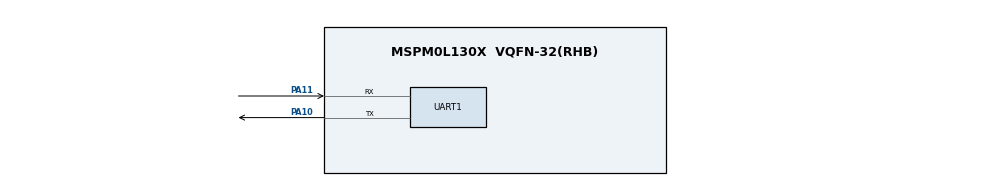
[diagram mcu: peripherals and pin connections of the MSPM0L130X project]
/**
 * @cliArgs --device "MSPM0L130X" --package "VQFN-32(RHB)" --part "Default" --product "mspm0_sdk@1.20.01.06"
 * @versions {"tool":"1.19.0+3426"}
 */

/**
 * Import the modules used in this configuration.
 */
const Board  = scripting.addModule("/ti/driverlib/Board");
const EVENT  = scripting.addModule("/ti/driverlib/EVENT");
const SYSCTL = scripting.addModule("/ti/driverlib/SYSCTL");
const UART   = scripting.addModule("/ti/driverlib/UART", {}, false);
const UART1  = UART.addInstance();

/**
 * Write custom configuration values to the imported modules.
 */
const gate6  = system.clockTree["MFCLKGATE"];
gate6.enable = true;

const gate7  = system.clockTree["MFPCLKGATE"];
gate7.enable = true;


SYSCTL.MFCLKEn     = true;
SYSCTL.MFPCLKEn    = true;
SYSCTL.clockTreeEn = true;

UART1.$name                    = "UART_0";
UART1.uartClkSrc               = "MFCLK";
UART1.targetBaudRate           = 115200;
UART1.enabledInterrupts        = ["RX"];
UART1.peripheral.$assign       = "UART1";
UART1.peripheral.rxPin.$assign = "PA11";
UART1.peripheral.txPin.$assign = "PA10";
UART1.txPinConfig.$name        = "ti_driverlib_gpio_GPIOPinGeneric0";
UART1.rxPinConfig.$name        = "ti_driverlib_gpio_GPIOPinGeneric1";

/**
 * Pinmux solution for unlocked pins/peripherals. This ensures that minor changes to the automatic solver in a future
 * version of the tool will not impact the pinmux you originally saw.  These lines can be completely deleted in order to
 * re-solve from scratch.
 */
Board.peripheral.$suggestSolution          = "DEBUGSS";
Board.peripheral.swclkPin.$suggestSolution = "PA20";
Board.peripheral.swdioPin.$suggestSolution = "PA19";
